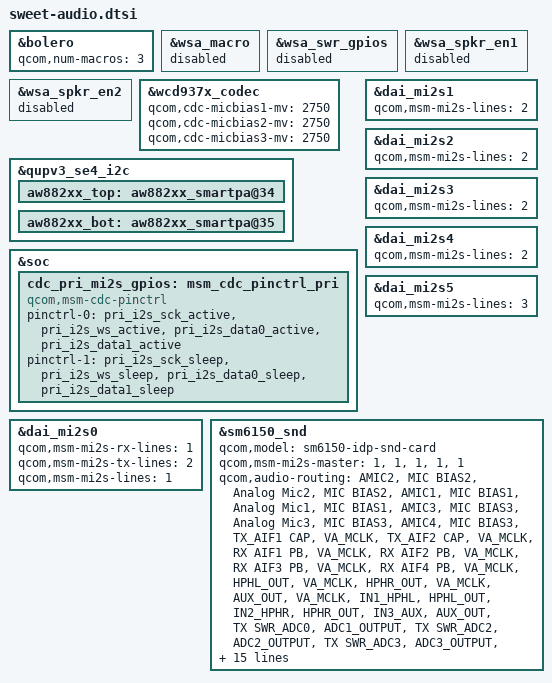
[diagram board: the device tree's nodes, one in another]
// SPDX-License-Identifier: GPL-2.0-only
/*
 * sweet audio, board layer on sdmmagpie-audio.dtsi: WCD937x for the analog
 * mics and headset (4.14 sweet-audio-overlay.dtsi), no WSA speakers, and two
 * Awinic AW882xx smart PAs (top and bottom speaker) on the primary MI2S.
 *
 * Routing follows violet-sm6150-audio.dtsi: 6.1 refuses non-supply ->
 * supply routes, so each Analog Mic is fed from its MIC BIAS, not the other
 * way round as in 4.14.
 */

&bolero {
	qcom,num-macros = <3>;
	/* the VA link uses va_macro_tx1: the VA macro must export its DAIs */
	/delete-property/ qcom,va-without-decimation;
};

&wsa_macro {
	status = "disabled";
};

&wsa_swr_gpios {
	status = "disabled";
};

&wsa_spkr_en1 {
	status = "disabled";
};

&wsa_spkr_en2 {
	status = "disabled";
};

&wcd937x_codec {
	qcom,cdc-micbias1-mv = <2750>;
	qcom,cdc-micbias2-mv = <2750>;
	qcom,cdc-micbias3-mv = <2750>;
};

/* the two smart PAs, already in the board DT from 4.14: label them for the card */
&qupv3_se4_i2c {
	aw882xx_top: aw882xx_smartpa@34 {
		#sound-dai-cells = <0>;
	};

	aw882xx_bot: aw882xx_smartpa@35 {
		#sound-dai-cells = <0>;
	};
};

&soc {
	cdc_pri_mi2s_gpios: msm_cdc_pinctrl_pri {
		compatible = "qcom,msm-cdc-pinctrl";
		pinctrl-names = "aud_active", "aud_sleep";
		pinctrl-0 = <&pri_i2s_sck_active &pri_i2s_ws_active
			     &pri_i2s_data0_active &pri_i2s_data1_active>;
		pinctrl-1 = <&pri_i2s_sck_sleep &pri_i2s_ws_sleep
			     &pri_i2s_data0_sleep &pri_i2s_data1_sleep>;
	};
};

&dai_mi2s0 {
	qcom,msm-mi2s-rx-lines = <1>;
	qcom,msm-mi2s-tx-lines = <2>;
};

/*
 * The 6.1 techpack reads one qcom,msm-mi2s-lines per MI2S interface (applied
 * to the capture direction for these nodes) instead of the 4.14 rx/tx pair.
 * Primary MI2S as on violet: speaker data out on SD0, the amplifier feedback
 * in on SD1.
 */
&dai_mi2s0 { qcom,msm-mi2s-lines = <1>; };
&dai_mi2s1 { qcom,msm-mi2s-lines = <2>; };
&dai_mi2s2 { qcom,msm-mi2s-lines = <2>; };
&dai_mi2s3 { qcom,msm-mi2s-lines = <2>; };
&dai_mi2s4 { qcom,msm-mi2s-lines = <2>; };
&dai_mi2s5 { qcom,msm-mi2s-lines = <3>; };

&sm6150_snd {
	qcom,model = "sm6150-idp-snd-card";
	qcom,msm-mi2s-master = <1>, <1>, <1>, <1>, <1>;
	qcom,audio-routing =
		"AMIC2", "MIC BIAS2",
		"Analog Mic2", "MIC BIAS2",
		"AMIC1", "MIC BIAS1",
		"Analog Mic1", "MIC BIAS1",
		"AMIC3", "MIC BIAS3",
		"Analog Mic3", "MIC BIAS3",
		"AMIC4", "MIC BIAS3",
		"TX_AIF1 CAP", "VA_MCLK",
		"TX_AIF2 CAP", "VA_MCLK",
		"RX AIF1 PB", "VA_MCLK",
		"RX AIF2 PB", "VA_MCLK",
		"RX AIF3 PB", "VA_MCLK",
		"RX AIF4 PB", "VA_MCLK",
		"HPHL_OUT", "VA_MCLK",
		"HPHR_OUT", "VA_MCLK",
		"AUX_OUT", "VA_MCLK",
		"IN1_HPHL", "HPHL_OUT",
		"IN2_HPHR", "HPHR_OUT",
		"IN3_AUX", "AUX_OUT",
		"TX SWR_ADC0", "ADC1_OUTPUT",
		"TX SWR_ADC2", "ADC2_OUTPUT",
		"TX SWR_ADC3", "ADC3_OUTPUT",
		"RX_TX DEC0_INP", "TX DEC0 MUX",
		"RX_TX DEC1_INP", "TX DEC1 MUX",
		"RX_TX DEC2_INP", "TX DEC2 MUX",
		"RX_TX DEC3_INP", "TX DEC3 MUX";
	qcom,msm-mbhc-hphl-swh = <1>;
	qcom,msm-mbhc-gnd-swh = <1>;
	qcom,cdc-dmic01-gpios = <&cdc_dmic01_gpios>;
	qcom,cdc-dmic23-gpios = <&cdc_dmic23_gpios>;
	qcom,pri-mi2s-gpios = <&cdc_pri_mi2s_gpios>;
	qcom,wsa-max-devs = <0>;
	/delete-property/ qcom,wsa-devs;
	qcom,codec-aux-devs = <&wcd937x_codec>;
	/* 6.1 matches link component names by device name: map them to the nodes */
	asoc-codec = <&stub_codec>, <&bolero>, <&wcd937x_codec>,
		     <&aw882xx_top>, <&aw882xx_bot>;
	asoc-codec-names = "msm-stub-codec.1", "bolero_codec", "wcd937x_codec",
			   "aw882xx_top", "aw882xx_bot";
};
